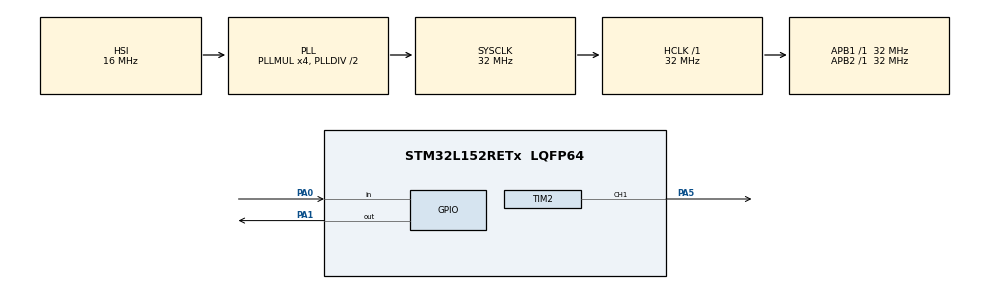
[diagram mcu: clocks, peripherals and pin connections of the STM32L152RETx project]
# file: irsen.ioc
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Mcu.Family=STM32L1
Mcu.Name=STM32L152RETx
Mcu.Package=LQFP64
NVIC.PriorityGroup=NVIC_PRIORITYGROUP_4
PA0-WKUP1.GPIO_PuPd=GPIO_PULLDOWN
PA0-WKUP1.Signal=GPIO_Input
PA1.GPIO_PuPd=GPIO_PULLDOWN
PA1.Signal=GPIO_Output
PA13.Mode=Serial_Wire
PA13.Signal=SYS_JTMS-SWDIO
PA14.Mode=Serial_Wire
PA14.Signal=SYS_JTCK-SWCLK
PA5.Signal=S_TIM2_CH1_ETR
ProjectManager.HeapSize=0x200
ProjectManager.StackSize=0x400
ProjectManager.TargetToolchain=MDK-ARM V5.32
RCC.48MHZClocksFreq_Value=32000000
RCC.AHBFreq_Value=32000000
RCC.APB1Freq_Value=32000000
RCC.APB1TimFreq_Value=32000000
RCC.APB2Freq_Value=32000000
RCC.APB2TimFreq_Value=32000000
RCC.HCLKFreq_Value=32000000
RCC.HSE_VALUE=24000000
RCC.HSI_VALUE=16000000
RCC.LSE_VALUE=32768
RCC.MSI_VALUE=2097000
RCC.PLLMUL=RCC_PLL_MUL4
RCC.SYSCLKFreq_VALUE=32000000
RCC.SYSCLKSource=RCC_SYSCLKSOURCE_PLLCLK
RCC.VCOOutputFreq_Value=64000000
SH.S_TIM2_CH1_ETR.0=TIM2_CH1,PWM Generation1 CH1
TIM2.Channel-PWM\ Generation1\ CH1=TIM_CHANNEL_1
TIM2.Period=19999
TIM2.Prescaler=31
VP_TIM2_VS_ClockSourceINT.Mode=Internal
board=custom

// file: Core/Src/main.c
/* USER CODE BEGIN Header */
/**
  ******************************************************************************
  * @file           : main.c
  * @brief          : Main program body
  ******************************************************************************
  * @attention
  *
  * Copyright (c) 2022 STMicroelectronics.
  * All rights reserved.
  *
  * This software is licensed under terms that can be found in the LICENSE file
  * in the root directory of this software component.
  * If no LICENSE file comes with this software, it is provided AS-IS.
  *
  ******************************************************************************
  */
/* USER CODE END Header */
#include "main.h"

TIM_HandleTypeDef htim2;

void SystemClock_Config(void);
static void MX_GPIO_Init(void);
static void MX_TIM2_Init(void);

/* USER CODE BEGIN 0 */
uint32_t map(uint32_t x, uint32_t in_min, uint32_t in_max, uint32_t out_min, uint32_t out_max) {
  return (x - in_min) * (out_max - out_min) / (in_max - in_min) + out_min;
}
void servo_write(TIM_HandleTypeDef *htim, uint16_t channel, uint16_t angle){
		uint16_t ccr = map(angle,0,180, 544, 2400);
		switch(channel){
			case TIM_CHANNEL_1:
				htim->Instance->CCR1=ccr;
				break;
			case TIM_CHANNEL_2:
				htim->Instance->CCR2=ccr;
				break;
			case TIM_CHANNEL_3:
				htim->Instance->CCR3=ccr;
				break;
			case TIM_CHANNEL_4:
				htim->Instance->CCR4=ccr;
				break;
		}

}

/* USER CODE END 0 */

int main(void)
{

  /* MCU Configuration--------------------------------------------------------*/

  /* Reset of all peripherals, Initializes the Flash interface and the Systick. */
  HAL_Init();

  /* Configure the system clock */
  SystemClock_Config();

  /* Initialize all configured peripherals */
  MX_GPIO_Init();
  MX_TIM2_Init();
  /* USER CODE BEGIN 2 */
	HAL_TIM_PWM_Start(&htim2,TIM_CHANNEL_1);

  /* USER CODE END 2 */

  /* Infinite loop */
  while (1)
  {

    /* USER CODE BEGIN 3 */
		if (HAL_GPIO_ReadPin(GPIOA,GPIO_PIN_0) == 1){

				HAL_GPIO_WritePin(GPIOA,GPIO_PIN_1,0);
				servo_write(&htim2, TIM_CHANNEL_1, 90);
				HAL_Delay(200);
		}
		else {
				HAL_GPIO_WritePin(GPIOA,GPIO_PIN_1,1);
				servo_write(&htim2, TIM_CHANNEL_1, 0);
				HAL_Delay(200);
		}
  }
  /* USER CODE END 3 */
}

void SystemClock_Config(void)
{
  RCC_OscInitTypeDef RCC_OscInitStruct = {0};
  RCC_ClkInitTypeDef RCC_ClkInitStruct = {0};

  /** Configure the main internal regulator output voltage
  */
  __HAL_PWR_VOLTAGESCALING_CONFIG(PWR_REGULATOR_VOLTAGE_SCALE1);
  /** Initializes the RCC Oscillators according to the specified parameters
  * in the RCC_OscInitTypeDef structure.
  */
  RCC_OscInitStruct.OscillatorType = RCC_OSCILLATORTYPE_HSI;
  RCC_OscInitStruct.HSIState = RCC_HSI_ON;
  RCC_OscInitStruct.HSICalibrationValue = RCC_HSICALIBRATION_DEFAULT;
  RCC_OscInitStruct.PLL.PLLState = RCC_PLL_ON;
  RCC_OscInitStruct.PLL.PLLSource = RCC_PLLSOURCE_HSI;
  RCC_OscInitStruct.PLL.PLLMUL = RCC_PLL_MUL4;
  RCC_OscInitStruct.PLL.PLLDIV = RCC_PLL_DIV2;
  if (HAL_RCC_OscConfig(&RCC_OscInitStruct) != HAL_OK)
  {
    Error_Handler();
  }
  /** Initializes the CPU, AHB and APB buses clocks
  */
  RCC_ClkInitStruct.ClockType = RCC_CLOCKTYPE_HCLK|RCC_CLOCKTYPE_SYSCLK
                              |RCC_CLOCKTYPE_PCLK1|RCC_CLOCKTYPE_PCLK2;
  RCC_ClkInitStruct.SYSCLKSource = RCC_SYSCLKSOURCE_PLLCLK;
  RCC_ClkInitStruct.AHBCLKDivider = RCC_SYSCLK_DIV1;
  RCC_ClkInitStruct.APB1CLKDivider = RCC_HCLK_DIV1;
  RCC_ClkInitStruct.APB2CLKDivider = RCC_HCLK_DIV1;

  if (HAL_RCC_ClockConfig(&RCC_ClkInitStruct, FLASH_LATENCY_1) != HAL_OK)
  {
    Error_Handler();
  }
}

static void MX_TIM2_Init(void)
{

  TIM_ClockConfigTypeDef sClockSourceConfig = {0};
  TIM_MasterConfigTypeDef sMasterConfig = {0};
  TIM_OC_InitTypeDef sConfigOC = {0};

  htim2.Instance = TIM2;
  htim2.Init.Prescaler = 31;
  htim2.Init.CounterMode = TIM_COUNTERMODE_UP;
  htim2.Init.Period = 19999;
  htim2.Init.ClockDivision = TIM_CLOCKDIVISION_DIV1;
  htim2.Init.AutoReloadPreload = TIM_AUTORELOAD_PRELOAD_DISABLE;
  if (HAL_TIM_Base_Init(&htim2) != HAL_OK)
  {
    Error_Handler();
  }
  sClockSourceConfig.ClockSource = TIM_CLOCKSOURCE_INTERNAL;
  if (HAL_TIM_ConfigClockSource(&htim2, &sClockSourceConfig) != HAL_OK)
  {
    Error_Handler();
  }
  if (HAL_TIM_PWM_Init(&htim2) != HAL_OK)
  {
    Error_Handler();
  }
  sMasterConfig.MasterOutputTrigger = TIM_TRGO_RESET;
  sMasterConfig.MasterSlaveMode = TIM_MASTERSLAVEMODE_DISABLE;
  if (HAL_TIMEx_MasterConfigSynchronization(&htim2, &sMasterConfig) != HAL_OK)
  {
    Error_Handler();
  }
  sConfigOC.OCMode = TIM_OCMODE_PWM1;
  sConfigOC.Pulse = 0;
  sConfigOC.OCPolarity = TIM_OCPOLARITY_HIGH;
  sConfigOC.OCFastMode = TIM_OCFAST_DISABLE;
  if (HAL_TIM_PWM_ConfigChannel(&htim2, &sConfigOC, TIM_CHANNEL_1) != HAL_OK)
  {
    Error_Handler();
  }
  HAL_TIM_MspPostInit(&htim2);

}

static void MX_GPIO_Init(void)
{
  GPIO_InitTypeDef GPIO_InitStruct = {0};

  /* GPIO Ports Clock Enable */
  __HAL_RCC_GPIOA_CLK_ENABLE();

  /*Configure GPIO pin Output Level */
  HAL_GPIO_WritePin(GPIOA, GPIO_PIN_1, GPIO_PIN_RESET);

  /*Configure GPIO pin : PA0 */
  GPIO_InitStruct.Pin = GPIO_PIN_0;
  GPIO_InitStruct.Mode = GPIO_MODE_INPUT;
  GPIO_InitStruct.Pull = GPIO_PULLDOWN;
  HAL_GPIO_Init(GPIOA, &GPIO_InitStruct);

  /*Configure GPIO pin : PA1 */
  GPIO_InitStruct.Pin = GPIO_PIN_1;
  GPIO_InitStruct.Mode = GPIO_MODE_OUTPUT_PP;
  GPIO_InitStruct.Pull = GPIO_PULLDOWN;
  GPIO_InitStruct.Speed = GPIO_SPEED_FREQ_LOW;
  HAL_GPIO_Init(GPIOA, &GPIO_InitStruct);

}

void Error_Handler(void)
{
  __disable_irq();
  while (1)
  {
  }
}
